# AT32F435 register map
Vendor: Keil; Series: AT32F435; File version: 1.0
CPU: CM4 r0p1, little endian, no MPU, FPU, 4 interrupt priority bits
Registers are 32-bit, read-write, reset 0x0 unless marked. A register's access mark holds for its fields unless they carry their own. Offsets are from the block's base; [hi:lo] are bit positions.

## ACC — HICK Auto Clock Calibration
Base 0x40017400
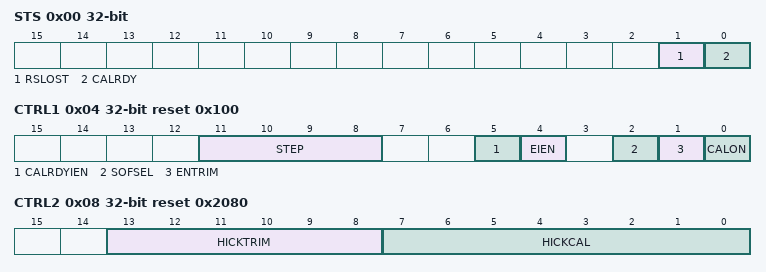
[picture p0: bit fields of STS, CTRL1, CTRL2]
0x00 STS ro — status register
  [1] RSLOST rw — Reference Signal Lost
    0=NotLost (Reference Signal is not lost); 1=Lost (Reference Signal is lost)
  [0] CALRDY rw — Internal high-speed clock calibration ready
    0=NotReady (Interal 8MHz oscillator calibration is not ready); 1=Ready (Interal 8MHz oscillator calibration is ready)
0x04 CTRL1 reset 0x100 — control register 1
  [11:8] STEP — Calibrated step
  [5] CALRDYIEN — CALRDY interrupt enable
    on read: 0=Disabled (Interrupt generation disabled); 1=Enabled (ACC interrupt is generated when CALRDY=1 in the ACC_STS register) | on write: 0=Disable (Interrupt generation disabled); 1=Enable (ACC interrupt is generated when CALRDY=1 in the ACC_STS register)
  [4] EIEN — RSLOST error interrupt enable
    on read: 0=Disabled (Interrupt generation disabled); 1=Enabled (ACC interrupt is generated when RSLOST=1 in the ACC_STS register) | on write: 0=Disable (Interrupt generation disabled); 1=Enable (ACC interrupt is generated when RSLOST=1 in the ACC_STS register)
  [2] SOFSEL — SOF Select
  [1] ENTRIM — Enable trim
    0=HICKCAL (HICKCAL is calibrated); 1=HICKTRIM (HICKTRIM is calibrated)
  [0] CALON — Calibration on
    on read: 0=Disabled (Calibration disabled); 1=Enabled (Calibration enabled, and starts searching for a pulse on the USB_SOF) | on write: 0=Disable (Calibration disabled); 1=Enable (Calibration enabled, and starts searching for a pulse on the USB_SOF)
0x08 CTRL2 reset 0x2080 — control register 2
  [13:8] HICKTRIM ro — Internal high-speed auto clock trimming
  [7:0] HICKCAL ro — Internal high-speed auto clock calibration
0x0C C1 16-bit reset 0x1F2C — compare value 1
0x10 C2 16-bit reset 0x1F40 — compare value 2
0x14 C3 16-bit reset 0x1F54 — compare value 3

## ADCCOM — ADC common area
Base 0x40012300
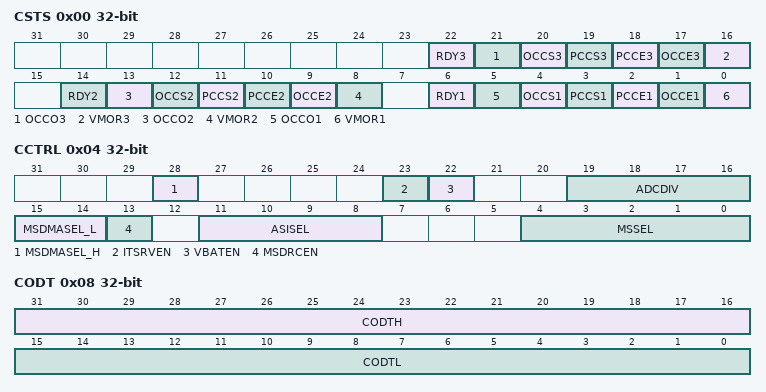
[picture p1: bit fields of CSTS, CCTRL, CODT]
0x00 CSTS ro — Common status register
  [22] RDY3 — ADC ready to conversion flag of ADC3
  [21] OCCO3 — Ordinary channel conversion overflow flag of ADC3
  [20] OCCS3 — Ordinary channel conversion start flag of ADC3
  [19] PCCS3 — Preempted channel conversion start flag of ADC3
  [18] PCCE3 — Preempted channels conversion end flag of ADC3
  [17] OCCE3 — Ordinary channels conversion end flag of ADC3
  [16] VMOR3 — Voltage monitoring out of range flag of ADC3
  [14] RDY2 — ADC ready to conversion flag of ADC2
  [13] OCCO2 — Ordinary channel conversion overflow flag of ADC2
  [12] OCCS2 — Ordinary channel conversion start flag of ADC2
  [11] PCCS2 — Preempted channel conversion start flag of ADC2
  [10] PCCE2 — Preempted channels conversion end flag of ADC2
  [9] OCCE2 — Ordinary channels conversion end flag of ADC2
  [8] VMOR2 — Voltage monitoring out of range flag of ADC2
  [6] RDY1 — ADC ready to conversion flag of ADC1
  [5] OCCO1 — Ordinary channel conversion overflow flag of ADC1
  [4] OCCS1 — Ordinary channel conversion start flag of ADC1
  [3] PCCS1 — Preempted channel conversion start flag of ADC1
  [2] PCCE1 — Preempted channels conversion end flag of ADC1
  [1] OCCE1 — Ordinary channels conversion end flag of ADC1
  [0] VMOR1 — Voltage monitoring out of range flag of ADC1
0x04 CCTRL — Common control register
  [28] MSDMASEL_H — High bit of ordinary channel DMA transfer mode select for master slave mode
  [23] ITSRVEN — Internal temperature sensor and VINTRV enable
  [22] VBATEN — VBAT enable
  [19:16] ADCDIV — ADC division
  [15:14] MSDMASEL_L — Low bit of ordinary channel DMA transfer mode select for master slave mode
  [13] MSDRCEN — Ordinary channel DMA request continuation enable for master slave mode
  [11:8] ASISEL — Adjacent ADC sampling interval select for ordinary shifting mode
  [4:0] MSSEL — Master slave mode select
0x08 CODT ro — Common Ordinary data register
  [31:16] CODTH — Ordinary conversion high halfword data for master slave mode
  [15:0] CODTL — Ordinary conversion low halfword data for master slave mode
